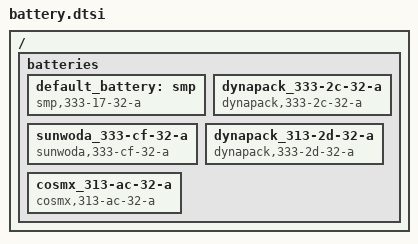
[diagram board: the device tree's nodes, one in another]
/* Copyright 2025 The ChromiumOS Authors
 * Use of this source code is governed by a BSD-style license that can be
 * found in the LICENSE file.
 */

/ {
	batteries {
		default_battery: smp {
			compatible = "smp,333-17-32-a", "battery-smart";
		};
		dynapack_333-2c-32-a {
			compatible = "dynapack,333-2c-32-a", "battery-smart";
		};
		sunwoda_333-cf-32-a {
			compatible = "sunwoda,333-cf-32-a", "battery-smart";
		};
		dynapack_313-2d-32-a {
			compatible = "dynapack,333-2d-32-a", "battery-smart";
		};
		cosmx_313-ac-32-a {
			compatible = "cosmx,313-ac-32-a", "battery-smart";
		};
	};
};
